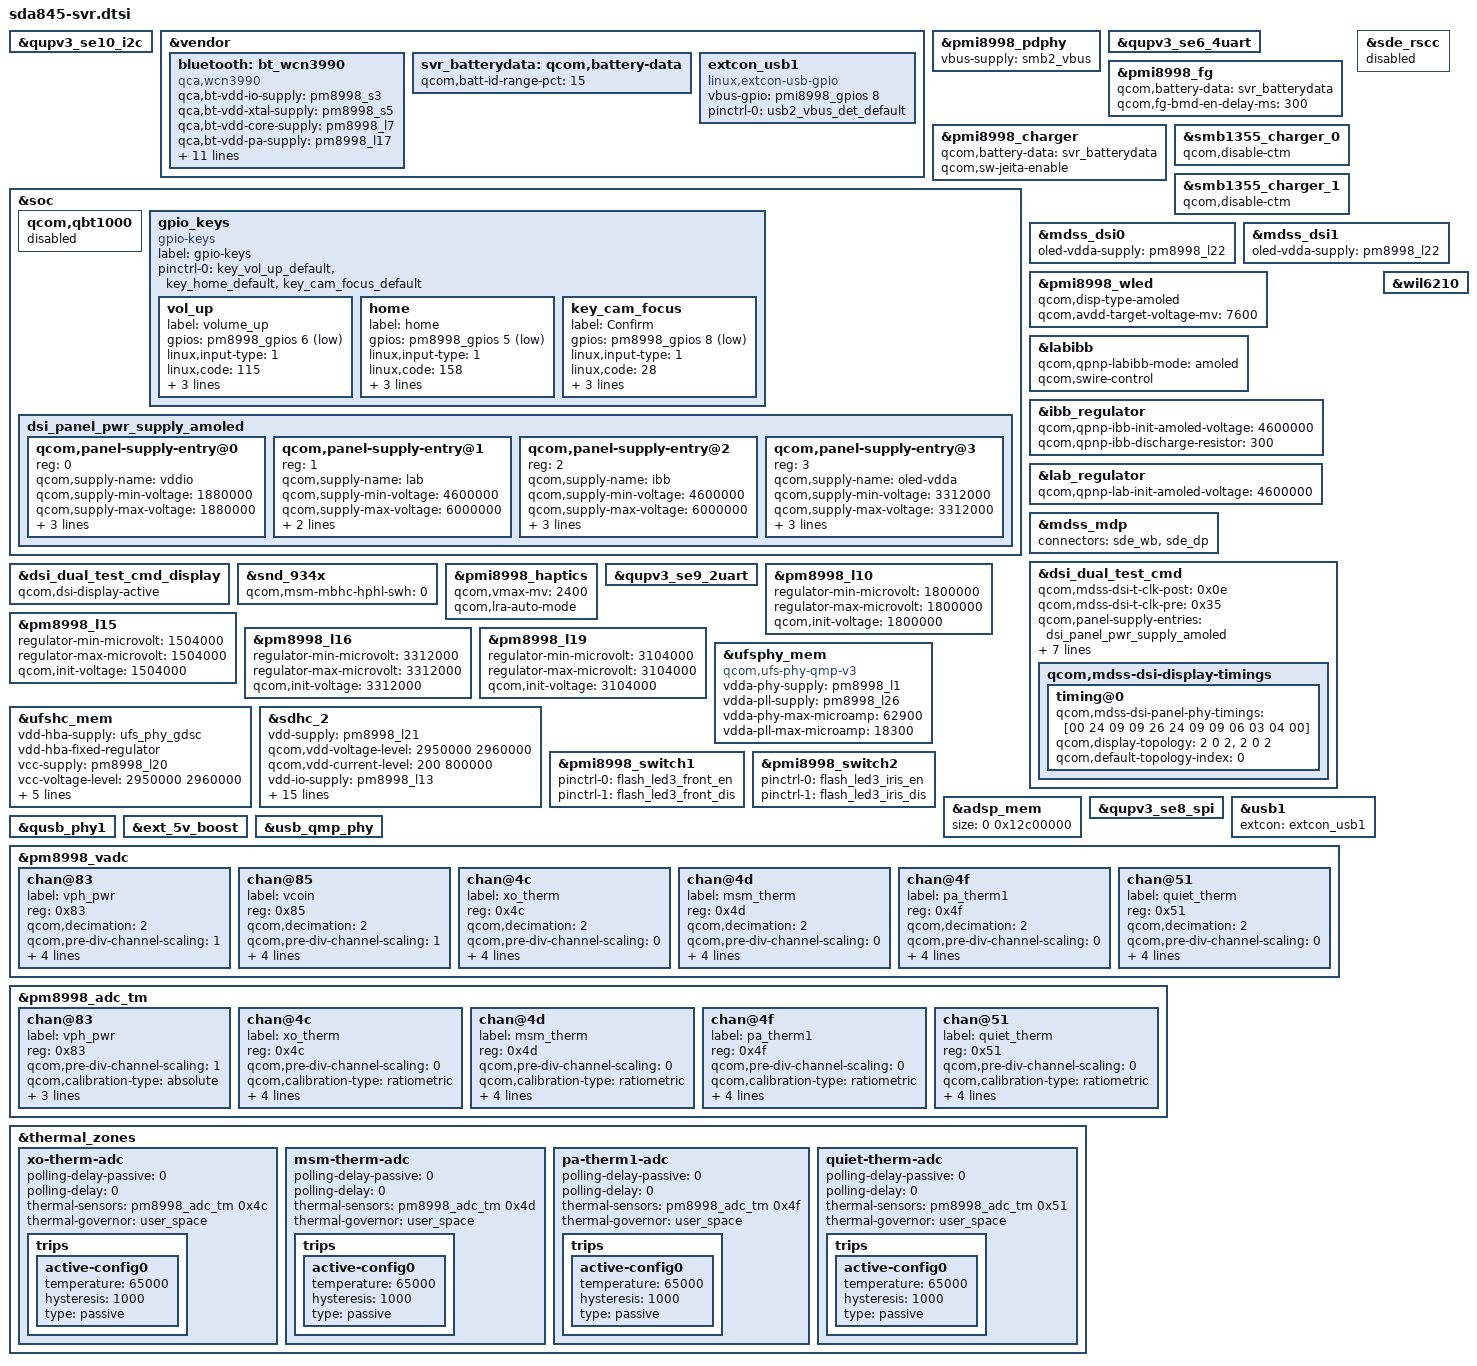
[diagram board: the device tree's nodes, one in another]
/* Copyright (c) 2018, The Linux Foundation. All rights reserved.
 *
 * This program is free software; you can redistribute it and/or modify
 * it under the terms of the GNU General Public License version 2 and
 * only version 2 as published by the Free Software Foundation.
 *
 * This program is distributed in the hope that it will be useful,
 * but WITHOUT ANY WARRANTY; without even the implied warranty of
 * MERCHANTABILITY or FITNESS FOR A PARTICULAR PURPOSE.  See the
 * GNU General Public License for more details.
 */

#include "sdm845-pmic-overlay.dtsi"
#include "sdm845-pinctrl-overlay.dtsi"
#include "sda845-svr-pinctrl-overlay.dtsi"
#include "sdm845-camera-sensor-svr.dtsi"
#include <dt-bindings/clock/mdss-10nm-pll-clk.h>

&qupv3_se10_i2c {
#include "smb1355.dtsi"
};

&vendor {
	bluetooth: bt_wcn3990 {
		compatible = "qca,wcn3990";
		qca,bt-vdd-io-supply = <&pm8998_s3>;
		qca,bt-vdd-xtal-supply = <&pm8998_s5>;
		qca,bt-vdd-core-supply = <&pm8998_l7>;
		qca,bt-vdd-pa-supply = <&pm8998_l17>;
		qca,bt-vdd-ldo-supply = <&pm8998_l25>;

		qca,bt-vdd-io-voltage-level = <1352000 1352000>;
		qca,bt-vdd-xtal-voltage-level = <2040000 2040000>;
		qca,bt-vdd-core-voltage-level = <1800000 1800000>;
		qca,bt-vdd-pa-voltage-level = <1304000 1304000>;
		qca,bt-vdd-ldo-voltage-level = <3312000 3312000>;

		qca,bt-vdd-io-current-level = <1>; /* LPM/PFM */
		qca,bt-vdd-xtal-current-level = <1>; /* LPM/PFM */
		qca,bt-vdd-core-current-level = <1>; /* LPM/PFM */
		qca,bt-vdd-pa-current-level = <1>; /* LPM/PFM */
		qca,bt-vdd-ldo-current-level = <1>; /* LPM/PFM */
	};

	svr_batterydata: qcom,battery-data {
		qcom,batt-id-range-pct = <15>;
		#include "fg-gen3-batterydata-demo-3600mah.dtsi"
	};
};

&pmi8998_pdphy {
	vbus-supply = <&smb2_vbus>;
};

&qupv3_se6_4uart {
	status = "ok";
};

&pmi8998_fg {
	qcom,battery-data = <&svr_batterydata>;
	qcom,fg-bmd-en-delay-ms = <300>;
};

&pmi8998_charger {
	qcom,battery-data = <&svr_batterydata>;
	qcom,sw-jeita-enable;
};

&qupv3_se10_i2c {
	status = "ok";
};

&smb1355_charger_0 {
	status = "ok";
	qcom,disable-ctm;
};

&smb1355_charger_1 {
	status = "ok";
	qcom,disable-ctm;
};

&soc {
	qcom,qbt1000 {
		status = "disabled";
	};

	gpio_keys {
		compatible = "gpio-keys";
		label = "gpio-keys";
		pinctrl-names = "default";
		pinctrl-0 = <&key_vol_up_default
				&key_home_default
				&key_cam_focus_default>;

		vol_up {
			label = "volume_up";
			gpios = <&pm8998_gpios 6 GPIO_ACTIVE_LOW>;
			linux,input-type = <1>;
			linux,code = <115>;
			gpio-key,wakeup;
			debounce-interval = <15>;
			linux,can-disable;
		};

		home {
			label = "home"; /* BACK Key*/
			gpios = <&pm8998_gpios 5 GPIO_ACTIVE_LOW>;
			linux,input-type = <1>;
			linux,code = <158>;
			gpio-key,wakeup;
			debounce-interval = <15>;
			linux,can-disable;
		};
		key_cam_focus {
			label = "Confirm"; /* Confirm Key*/
			gpios = <&pm8998_gpios 8 GPIO_ACTIVE_LOW>;
			linux,input-type = <1>;
			linux,code = <28>;
			gpio-key,wakeup;
			debounce-interval = <15>;
			linux,can-disable;
		};
	};

	dsi_panel_pwr_supply_amoled: dsi_panel_pwr_supply_amoled {
		#address-cells = <1>;
		#size-cells = <0>;

		qcom,panel-supply-entry@0 {
			reg = <0>;
			qcom,supply-name = "vddio";
			qcom,supply-min-voltage = <1880000>;
			qcom,supply-max-voltage = <1880000>;
			qcom,supply-enable-load = <62000>;
			qcom,supply-disable-load = <80>;
			qcom,supply-post-on-sleep = <20>;
		};

		qcom,panel-supply-entry@1 {
			reg = <1>;
			qcom,supply-name = "lab";
			qcom,supply-min-voltage = <4600000>;
			qcom,supply-max-voltage = <6000000>;
			qcom,supply-enable-load = <100000>;
			qcom,supply-disable-load = <100>;
		};

		qcom,panel-supply-entry@2 {
			reg = <2>;
			qcom,supply-name = "ibb";
			qcom,supply-min-voltage = <4600000>;
			qcom,supply-max-voltage = <6000000>;
			qcom,supply-enable-load = <100000>;
			qcom,supply-disable-load = <100>;
			qcom,supply-post-on-sleep = <20>;
		};
		qcom,panel-supply-entry@3 {
			reg = <3>;
			qcom,supply-name = "oled-vdda";
			qcom,supply-min-voltage = <3312000>;
			qcom,supply-max-voltage = <3312000>;
			qcom,supply-enable-load = <857000>;
			qcom,supply-disable-load = <0>;
			qcom,supply-post-on-sleep = <0>;
		};
	};
};

&sde_rscc {
	status = "disabled";
};

&mdss_dsi0 {
	oled-vdda-supply = <&pm8998_l22>;
};

&mdss_dsi1 {
	oled-vdda-supply = <&pm8998_l22>;
};

&pmi8998_wled {
	status = "ok";
	qcom,disp-type-amoled;
	qcom,avdd-target-voltage-mv = <7600>;
};

&labibb {
	status = "ok";
	qcom,qpnp-labibb-mode = "amoled";
	qcom,swire-control;
};

&ibb_regulator {
	status = "ok";
	qcom,qpnp-ibb-init-amoled-voltage = <4600000>;
	qcom,qpnp-ibb-discharge-resistor = <300>;
};

&lab_regulator {
	status = "ok";
	qcom,qpnp-lab-init-amoled-voltage = <4600000>;
};

&mdss_mdp {
	connectors = <&sde_wb &sde_dp>;
};

&dsi_dual_test_cmd {
	qcom,mdss-dsi-t-clk-post = <0x0e>;
	qcom,mdss-dsi-t-clk-pre = <0x35>;
	qcom,mdss-dsi-display-timings {
		timing@0{
			qcom,mdss-dsi-panel-phy-timings =
				[00 24 09 09 26 24 09 09 06 03 04 00];
			qcom,display-topology = <2 0 2>,
						<2 0 2>;
			qcom,default-topology-index = <0>;
		};
	};
};

&dsi_dual_test_cmd {
	qcom,panel-supply-entries = <&dsi_panel_pwr_supply_amoled>;
	qcom,mdss-dsi-bl-pmic-control-type = "bl_ctrl_dcs";
	qcom,mdss-dsi-bl-min-level = <1>;
	qcom,mdss-dsi-bl-max-level = <255>;
	qcom,mdss-dsi-mode-sel-gpio-state = "dual_port";
	qcom,platform-reset-gpio = <&tlmm 6 0>;
	qcom,platform-te-gpio = <&tlmm 10 0>;
};

&dsi_dual_test_cmd_display {
	qcom,dsi-display-active;
};

&snd_934x {
	qcom,msm-mbhc-hphl-swh = <0>;
};

&pmi8998_haptics {
	qcom,vmax-mv = <2400>;
	qcom,lra-auto-mode;
	status = "okay";
};

&qupv3_se9_2uart {
	status = "ok";
};

&mdss_mdp {
	#cooling-cells = <2>;
};

&pm8998_l10 {
	regulator-min-microvolt = <1800000>;
	regulator-max-microvolt = <1800000>;
	qcom,init-voltage = <1800000>;
};

&pm8998_l15 {
	regulator-min-microvolt = <1504000>;
	regulator-max-microvolt = <1504000>;
	qcom,init-voltage = <1504000>;
};

&pm8998_l16 {
	regulator-min-microvolt = <3312000>;
	regulator-max-microvolt = <3312000>;
	qcom,init-voltage = <3312000>;
};

&pm8998_l19 {
	regulator-min-microvolt = <3104000>;
	regulator-max-microvolt = <3104000>;
	qcom,init-voltage = <3104000>;
};


&ufsphy_mem {
	compatible = "qcom,ufs-phy-qmp-v3";

	vdda-phy-supply = <&pm8998_l1>; /* 0.88v */
	vdda-pll-supply = <&pm8998_l26>; /* 1.2v */
	vdda-phy-max-microamp = <62900>;
	vdda-pll-max-microamp = <18300>;

	status = "ok";
};

&ufshc_mem {
	vdd-hba-supply = <&ufs_phy_gdsc>;
	vdd-hba-fixed-regulator;
	vcc-supply = <&pm8998_l20>;
	vcc-voltage-level = <2950000 2960000>;
	vccq2-supply = <&pm8998_s4>;
	vcc-max-microamp = <600000>;
	vccq2-max-microamp = <600000>;

	qcom,vddp-ref-clk-supply = <&pm8998_l2>;
	qcom,vddp-ref-clk-max-microamp = <100>;

	status = "ok";
};

&sdhc_2 {
	vdd-supply = <&pm8998_l21>;
	qcom,vdd-voltage-level = <2950000 2960000>;
	qcom,vdd-current-level = <200 800000>;

	vdd-io-supply = <&pm8998_l13>;
	qcom,vdd-io-voltage-level = <1808000 2960000>;
	qcom,vdd-io-current-level = <200 22000>;

	pinctrl-names = "active", "sleep", "ds_400KHz",
			"ds_50MHz", "ds_100MHz", "ds_200MHz";
	pinctrl-0 = <&sdc2_clk_on  &sdc2_cmd_on &sdc2_data_on &storage_cd>;
	pinctrl-1 = <&sdc2_clk_off &sdc2_cmd_off &sdc2_data_off &storage_cd>;
	pinctrl-2 = <&sdc2_clk_ds_400KHz
			&sdc2_cmd_ds_400KHz &sdc2_data_ds_400KHz>;
	pinctrl-3 = <&sdc2_clk_ds_50MHz
			&sdc2_cmd_ds_50MHz &sdc2_data_ds_50MHz>;
	pinctrl-4 = <&sdc2_clk_ds_100MHz
			&sdc2_cmd_ds_100MHz &sdc2_data_ds_100MHz>;
	pinctrl-5 = <&sdc2_clk_ds_200MHz
			&sdc2_cmd_ds_200MHz &sdc2_data_ds_200MHz>;

	cd-gpios = <&tlmm 126 GPIO_ACTIVE_LOW>;

	status = "ok";
};

&pmi8998_switch1 {
	pinctrl-names = "led_enable", "led_disable";
	pinctrl-0 = <&flash_led3_front_en>;
	pinctrl-1 = <&flash_led3_front_dis>;
};

&pmi8998_switch2 {
	pinctrl-names = "led_enable", "led_disable";
	pinctrl-0 = <&flash_led3_iris_en>;
	pinctrl-1 = <&flash_led3_iris_dis>;
};

&vendor {
	extcon_usb1: extcon_usb1 {
		compatible = "linux,extcon-usb-gpio";
		vbus-gpio = <&pmi8998_gpios 8 GPIO_ACTIVE_HIGH>;

		pinctrl-names = "default";
		pinctrl-0 = <&usb2_vbus_det_default>;
	};
};

&adsp_mem {
	size = <0 0x12c00000>;
};

&qupv3_se9_2uart {
	status = "ok";
};

&qupv3_se8_spi {
	status = "ok";
};

&qupv3_se10_i2c {
	status = "ok";
};

&qupv3_se6_4uart {
	status = "ok";
};

&usb1 {
	status = "okay";
	extcon = <&extcon_usb1>;
};

&qusb_phy1 {
	status = "okay";
};

&ext_5v_boost {
	status = "ok";
};

&usb_qmp_phy {
	status = "okay";
};

&pm8998_vadc {
	chan@83 {
		label = "vph_pwr";
		reg = <0x83>;
		qcom,decimation = <2>;
		qcom,pre-div-channel-scaling = <1>;
		qcom,calibration-type = "absolute";
		qcom,scale-function = <0>;
		qcom,hw-settle-time = <0>;
		qcom,fast-avg-setup = <0>;
	};

	chan@85 {
		label = "vcoin";
		reg = <0x85>;
		qcom,decimation = <2>;
		qcom,pre-div-channel-scaling = <1>;
		qcom,calibration-type = "absolute";
		qcom,scale-function = <0>;
		qcom,hw-settle-time = <0>;
		qcom,fast-avg-setup = <0>;
	};

	chan@4c {
		label = "xo_therm";
		reg = <0x4c>;
		qcom,decimation = <2>;
		qcom,pre-div-channel-scaling = <0>;
		qcom,calibration-type = "ratiometric";
		qcom,scale-function = <4>;
		qcom,hw-settle-time = <2>;
		qcom,fast-avg-setup = <0>;
	};

	chan@4d {
		label = "msm_therm";
		reg = <0x4d>;
		qcom,decimation = <2>;
		qcom,pre-div-channel-scaling = <0>;
		qcom,calibration-type = "ratiometric";
		qcom,scale-function = <2>;
		qcom,hw-settle-time = <2>;
		qcom,fast-avg-setup = <0>;
	};

	chan@4f {
		label = "pa_therm1";
		reg = <0x4f>;
		qcom,decimation = <2>;
		qcom,pre-div-channel-scaling = <0>;
		qcom,calibration-type = "ratiometric";
		qcom,scale-function = <2>;
		qcom,hw-settle-time = <2>;
		qcom,fast-avg-setup = <0>;
	};

	chan@51 {
		label = "quiet_therm";
		reg = <0x51>;
		qcom,decimation = <2>;
		qcom,pre-div-channel-scaling = <0>;
		qcom,calibration-type = "ratiometric";
		qcom,scale-function = <2>;
		qcom,hw-settle-time = <2>;
		qcom,fast-avg-setup = <0>;
	};
};

&pm8998_adc_tm {
	chan@83 {
		label = "vph_pwr";
		reg = <0x83>;
		qcom,pre-div-channel-scaling = <1>;
		qcom,calibration-type = "absolute";
		qcom,scale-function = <0>;
		qcom,hw-settle-time = <0>;
		qcom,btm-channel-number = <0x60>;
	};

	chan@4c {
		label = "xo_therm";
		reg = <0x4c>;
		qcom,pre-div-channel-scaling = <0>;
		qcom,calibration-type = "ratiometric";
		qcom,scale-function = <4>;
		qcom,hw-settle-time = <2>;
		qcom,btm-channel-number = <0x68>;
		qcom,thermal-node;
	};

	chan@4d {
		label = "msm_therm";
		reg = <0x4d>;
		qcom,pre-div-channel-scaling = <0>;
		qcom,calibration-type = "ratiometric";
		qcom,scale-function = <2>;
		qcom,hw-settle-time = <2>;
		qcom,btm-channel-number = <0x70>;
		qcom,thermal-node;
	};

	chan@4f {
		label = "pa_therm1";
		reg = <0x4f>;
		qcom,pre-div-channel-scaling = <0>;
		qcom,calibration-type = "ratiometric";
		qcom,scale-function = <2>;
		qcom,hw-settle-time = <2>;
		qcom,btm-channel-number = <0x78>;
		qcom,thermal-node;
	};

	chan@51 {
		label = "quiet_therm";
		reg = <0x51>;
		qcom,pre-div-channel-scaling = <0>;
		qcom,calibration-type = "ratiometric";
		qcom,scale-function = <2>;
		qcom,hw-settle-time = <2>;
		qcom,btm-channel-number = <0x80>;
		qcom,thermal-node;
	};
};

&thermal_zones {
	xo-therm-adc {
		polling-delay-passive = <0>;
		polling-delay = <0>;
		thermal-sensors = <&pm8998_adc_tm 0x4c>;
		thermal-governor = "user_space";

		trips {
			active-config0 {
				temperature = <65000>;
				hysteresis = <1000>;
				type = "passive";
			};
		};
	};

	msm-therm-adc {
		polling-delay-passive = <0>;
		polling-delay = <0>;
		thermal-sensors = <&pm8998_adc_tm 0x4d>;
		thermal-governor = "user_space";

		trips {
			active-config0 {
				temperature = <65000>;
				hysteresis = <1000>;
				type = "passive";
			};
		};
	};

	pa-therm1-adc {
		polling-delay-passive = <0>;
		polling-delay = <0>;
		thermal-sensors = <&pm8998_adc_tm 0x4f>;
		thermal-governor = "user_space";

		trips {
			active-config0 {
				temperature = <65000>;
				hysteresis = <1000>;
				type = "passive";
			};
		};
	};

	quiet-therm-adc {
		polling-delay-passive = <0>;
		polling-delay = <0>;
		thermal-sensors = <&pm8998_adc_tm 0x51>;
		thermal-governor = "user_space";

		trips {
			active-config0 {
				temperature = <65000>;
				hysteresis = <1000>;
				type = "passive";
			};
		};
	};
};

&wil6210 {
	status = "ok";
};
